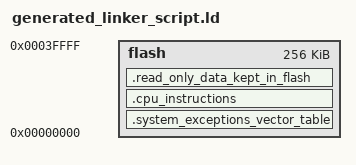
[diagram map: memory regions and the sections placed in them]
# generated/generated_linker_files/generated_linker_script.ld - do not edit - generated by build.zig

MEMORY {
    flash : ORIGIN = 0x0, LENGTH = 0x40000
}

SECTIONS {
    .system_exceptions_vector_table : {
        _start = .;
        KEEP(*(.vector_table))
    } > flash
    .cpu_instructions : {
        *(.text.*)
    } > flash
    .read_only_data_kept_in_flash : {
        *(.rodata)
        *(.rodata.*)
    } > flash
}

MEMORY {
    ram : ORIGIN = 0x20000000, LENGTH = 0x4000
}

SECTIONS {
    .determine_load_start_for_data_loaded_in_flash_that_program_must_copy_to_ram : {
        __data_loaded_in_flash_that_program_must_copy_to_ram_load_start = .;
    } > flash
    .data_loaded_in_flash_that_program_must_copy_to_ram : AT(__data_loaded_in_flash_that_program_must_copy_to_ram_load_start) {
        __data_loaded_in_flash_that_program_must_copy_to_ram_start = .;
        *(.data)
        __data_loaded_in_flash_that_program_must_copy_to_ram_end = .;
    } > ram
    .data_that_program_must_set_to_zero (NOLOAD) : {
        __data_that_program_must_set_to_zero_start = .;
        *(.bss)
        __data_that_program_must_set_to_zero_end = .;
    } > ram
}

# .ARM.exidx must be discarded until "Provide -fno-unwind-tables" is resolved https://github.com/ziglang/zig/issues/5464

SECTIONS {
    /DISCARD/ : {
        *(.ARM.exidx)
    }
}
